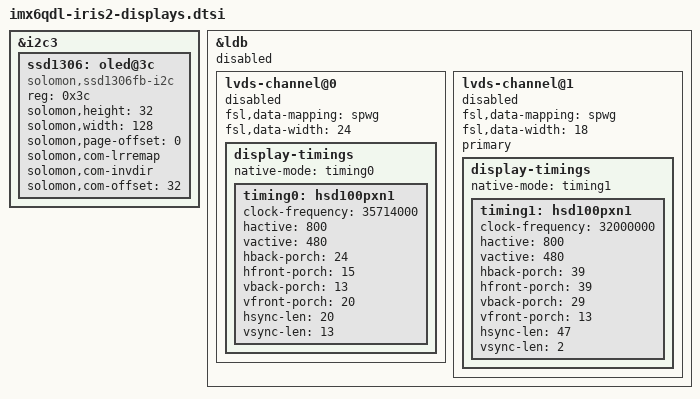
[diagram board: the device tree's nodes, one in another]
/*
 * Copyright (C) 2015-2017 Variscite Ltd.
 *
 * This program is free software; you can redistribute it and/or modify
 * it under the terms of the GNU General Public License version 2 as
 * published by the Free Software Foundation.
 *
 * OLED Dis
 */

&i2c3 {
	ssd1306: oled@3c {
		compatible = "solomon,ssd1306fb-i2c";
		reg = <0x3c>;
		solomon,height = <32>;
		solomon,width = <128>;
		solomon,page-offset = <0>;
		solomon,com-lrremap;
		solomon,com-invdir;
		solomon,com-offset = <32>;
	};
};

&ldb {
	status = "disabled";

	lvds-channel@0 {
		fsl,data-mapping = "spwg";
		fsl,data-width = <24>;
		status = "disabled";

		display-timings {
			native-mode = <&timing0>;
			timing0: hsd100pxn1 {
				clock-frequency = <35714000>;
				hactive = <800>;
				vactive = <480>;
				hback-porch = <24>;
				hfront-porch = <15>;
				vback-porch = <13>;
				vfront-porch = <20>;
				hsync-len = <20>;
				vsync-len = <13>;
			};
		};
	};

	lvds-channel@1 {
		fsl,data-mapping = "spwg";
		fsl,data-width = <18>;
		primary;
		status = "disabled";

		display-timings {
			native-mode = <&timing1>;
			timing1: hsd100pxn1 {
				clock-frequency = <32000000>;
				hactive = <800>;
				vactive = <480>;
				hback-porch = <39>;
				hfront-porch = <39>;
				vback-porch = <29>;
				vfront-porch = <13>;
				hsync-len = <47>;
				vsync-len = <2>;
			};
		};
	};
};
